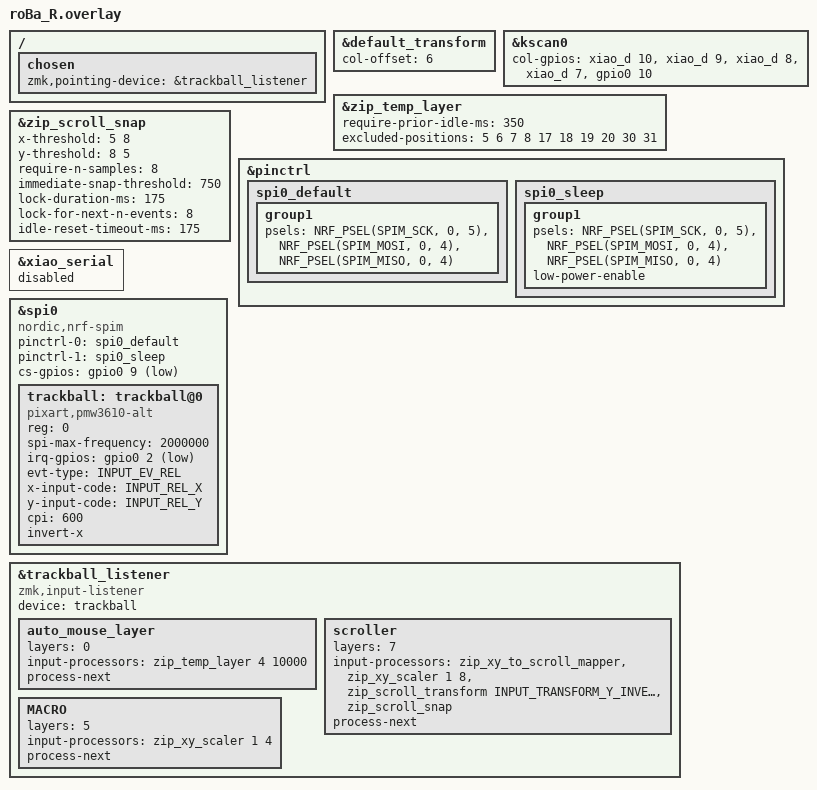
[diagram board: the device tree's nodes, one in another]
#include "roBa.dtsi"
#include <zephyr/dt-bindings/input/input-event-codes.h>

/ {
    chosen {
        zmk,pointing-device = &trackball_listener;
    };
};

&default_transform {
    col-offset = <6>;
};

&kscan0 {
        col-gpios
            = <&xiao_d 10 GPIO_ACTIVE_HIGH>
            , <&xiao_d 9 GPIO_ACTIVE_HIGH>
            , <&xiao_d 8 GPIO_ACTIVE_HIGH>
            , <&xiao_d 7 GPIO_ACTIVE_HIGH>
            , <&gpio0 10 GPIO_ACTIVE_HIGH>
            ;
};

&zip_temp_layer {
    require-prior-idle-ms = <350>;
    excluded-positions = <5 6 7 8 17 18 19 20 30 31>;
};

&zip_scroll_snap {
    x-threshold = <5 8>;
    y-threshold = <8 5>;
    require-n-samples = <8>;
    immediate-snap-threshold = <750>;
    lock-duration-ms = <175>;
    lock-for-next-n-events = <8>;
    idle-reset-timeout-ms = <175>;
};

&pinctrl {
    spi0_default: spi0_default {
        group1 {
            psels = <NRF_PSEL(SPIM_SCK, 0, 5)>,
                <NRF_PSEL(SPIM_MOSI, 0, 4)>,
                <NRF_PSEL(SPIM_MISO, 0, 4)>;
        };
    };

    spi0_sleep: spi0_sleep {
        group1 {
            psels = <NRF_PSEL(SPIM_SCK, 0, 5)>,
                <NRF_PSEL(SPIM_MOSI, 0, 4)>,
                <NRF_PSEL(SPIM_MISO, 0, 4)>;
            low-power-enable;
        };
    };
};

&xiao_serial {
    status = "disabled";
};

&spi0 {
    status = "okay";
    compatible = "nordic,nrf-spim";
    pinctrl-0 = <&spi0_default>;
    pinctrl-1 = <&spi0_sleep>;
    pinctrl-names = "default", "sleep";
    cs-gpios = <&gpio0 9 GPIO_ACTIVE_LOW>;

    trackball: trackball@0 {
        status = "okay";
        compatible = "pixart,pmw3610-alt";
        reg = <0>;
        spi-max-frequency = <2000000>;
        irq-gpios = <&gpio0 2 (GPIO_ACTIVE_LOW | GPIO_PULL_UP)>;
        evt-type = <INPUT_EV_REL>;
        x-input-code = <INPUT_REL_X>;
        y-input-code = <INPUT_REL_Y>;
        cpi = <600>;
        invert-x;
    };
};

&trackball_listener {
    status = "okay";
    compatible = "zmk,input-listener";
    device = <&trackball>;

    auto_mouse_layer {
        layers = <0>;
        input-processors = <
            &zip_temp_layer 4 10000
        >;
        process-next;
    };

    scroller {
        layers = <7>;
        input-processors = <
            &zip_xy_to_scroll_mapper
            &zip_xy_scaler 1 8
            &zip_scroll_transform INPUT_TRANSFORM_Y_INVERT
            &zip_scroll_snap
        >;
        process-next;
    };

    MACRO {
        layers = <5>;
        input-processors = <
            &zip_xy_scaler 1 4
        >;
        process-next;
    };
};
